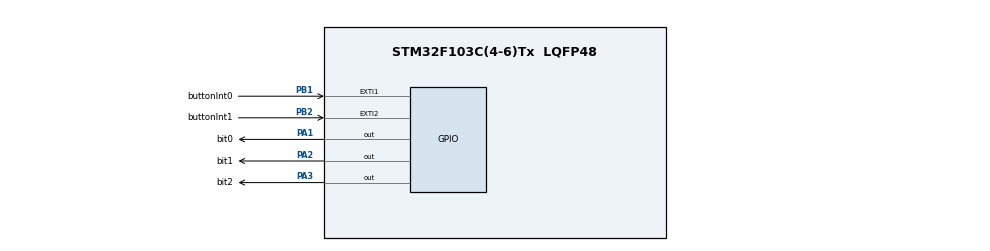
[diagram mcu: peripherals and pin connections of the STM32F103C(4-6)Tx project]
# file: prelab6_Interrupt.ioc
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Mcu.Family=STM32F1
Mcu.Name=STM32F103C(4-6)Tx
Mcu.Package=LQFP48
NVIC.EXTI1_IRQn=true\:2\:0\:true\:false\:true\:true\:true\:true
NVIC.EXTI2_IRQn=true\:3\:0\:true\:false\:true\:true\:true\:true
NVIC.PriorityGroup=NVIC_PRIORITYGROUP_4
PA1.GPIO_Label=bit0
PA1.Signal=GPIO_Output
PA2.GPIO_Label=bit1
PA2.Signal=GPIO_Output
PA3.GPIO_Label=bit2
PA3.Signal=GPIO_Output
PB1.GPIO_Label=buttonInt0
PB1.Signal=GPXTI1
PB2.GPIO_Label=buttonInt1
PB2.Signal=GPXTI2
ProjectManager.HeapSize=0x200
ProjectManager.StackSize=0x400
ProjectManager.TargetToolchain=MDK-ARM V5.32
RCC.APB1Freq_Value=8000000
RCC.APB2Freq_Value=8000000
VP_SYS_VS_ND.Mode=No_Debug
board=custom

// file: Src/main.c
/* USER CODE BEGIN Header */
/**
  ******************************************************************************
  * @file           : main.c
  * @brief          : Main program body
  ******************************************************************************
  * @attention
  *
  * Copyright (c) 2023 STMicroelectronics.
  * All rights reserved.
  *
  * This software is licensed under terms that can be found in the LICENSE file
  * in the root directory of this software component.
  * If no LICENSE file comes with this software, it is provided AS-IS.
  *
  ******************************************************************************
  */
/* USER CODE END Header */
#include "main.h"

/* USER CODE BEGIN PV */
	 uint16_t num_press = 0;
	 uint16_t timeSpend = 200;
/* USER CODE END PV */

void SystemClock_Config(void);
static void MX_GPIO_Init(void);

int main(void)
{

  /* MCU Configuration--------------------------------------------------------*/

  /* Reset of all peripherals, Initializes the Flash interface and the Systick. */
  HAL_Init();

  /* Configure the system clock */
  SystemClock_Config();

  /* Initialize all configured peripherals */
  MX_GPIO_Init();

  /* Infinite loop */
  /* USER CODE BEGIN WHILE */

  while (1)
  {
			HAL_Delay(timeSpend);
			update_leds(timeSpend);

    /* USER CODE END WHILE */

  }
}

void SystemClock_Config(void)
{
  RCC_OscInitTypeDef RCC_OscInitStruct = {0};
  RCC_ClkInitTypeDef RCC_ClkInitStruct = {0};

  /** Initializes the RCC Oscillators according to the specified parameters
  * in the RCC_OscInitTypeDef structure.
  */
  RCC_OscInitStruct.OscillatorType = RCC_OSCILLATORTYPE_HSI;
  RCC_OscInitStruct.HSIState = RCC_HSI_ON;
  RCC_OscInitStruct.HSICalibrationValue = RCC_HSICALIBRATION_DEFAULT;
  RCC_OscInitStruct.PLL.PLLState = RCC_PLL_NONE;
  if (HAL_RCC_OscConfig(&RCC_OscInitStruct) != HAL_OK)
  {
    Error_Handler();
  }

  /** Initializes the CPU, AHB and APB buses clocks
  */
  RCC_ClkInitStruct.ClockType = RCC_CLOCKTYPE_HCLK|RCC_CLOCKTYPE_SYSCLK
                              |RCC_CLOCKTYPE_PCLK1|RCC_CLOCKTYPE_PCLK2;
  RCC_ClkInitStruct.SYSCLKSource = RCC_SYSCLKSOURCE_HSI;
  RCC_ClkInitStruct.AHBCLKDivider = RCC_SYSCLK_DIV1;
  RCC_ClkInitStruct.APB1CLKDivider = RCC_HCLK_DIV1;
  RCC_ClkInitStruct.APB2CLKDivider = RCC_HCLK_DIV1;

  if (HAL_RCC_ClockConfig(&RCC_ClkInitStruct, FLASH_LATENCY_0) != HAL_OK)
  {
    Error_Handler();
  }
}

static void MX_GPIO_Init(void)
{
  GPIO_InitTypeDef GPIO_InitStruct = {0};

  /* GPIO Ports Clock Enable */
  __HAL_RCC_GPIOA_CLK_ENABLE();
  __HAL_RCC_GPIOB_CLK_ENABLE();

  /*Configure GPIO pin Output Level */
  HAL_GPIO_WritePin(GPIOA, bit0_Pin|bit1_Pin|bit2_Pin, GPIO_PIN_RESET);

  /*Configure GPIO pins : bit0_Pin bit1_Pin bit2_Pin */
  GPIO_InitStruct.Pin = bit0_Pin|bit1_Pin|bit2_Pin;
  GPIO_InitStruct.Mode = GPIO_MODE_OUTPUT_PP;
  GPIO_InitStruct.Pull = GPIO_NOPULL;
  GPIO_InitStruct.Speed = GPIO_SPEED_FREQ_LOW;
  HAL_GPIO_Init(GPIOA, &GPIO_InitStruct);

  /*Configure GPIO pins : buttonInt0_Pin buttonInt1_Pin */
  GPIO_InitStruct.Pin = buttonInt0_Pin|buttonInt1_Pin;
  GPIO_InitStruct.Mode = GPIO_MODE_IT_RISING;
  GPIO_InitStruct.Pull = GPIO_NOPULL;
  HAL_GPIO_Init(GPIOB, &GPIO_InitStruct);

  /* EXTI interrupt init*/
  HAL_NVIC_SetPriority(EXTI1_IRQn, 2, 0);
  HAL_NVIC_EnableIRQ(EXTI1_IRQn);

  HAL_NVIC_SetPriority(EXTI2_IRQn, 3, 0);
  HAL_NVIC_EnableIRQ(EXTI2_IRQn);

}

/* USER CODE BEGIN 4 */
void update_leds(uint16_t timeSpend){

			uint16_t myArray[7] ={0, 1, 2, 4, 2, 1, 0};
			num_press++;
			GPIO_PinState bit0_value, bit1_value, bit2_value;

			bit0_value = ( myArray[num_press % 7] & (uint16_t)1) ? GPIO_PIN_SET : GPIO_PIN_RESET;
			bit1_value = ( myArray[num_press % 7] & (uint16_t)2) ? GPIO_PIN_SET : GPIO_PIN_RESET;
			bit2_value = ( myArray[num_press % 7] & (uint16_t)4) ? GPIO_PIN_SET : GPIO_PIN_RESET;

		bit0_GPIO_Port->BSRR = (bit0_value ? bit0_Pin : (bit0_Pin << 16u)) | (bit1_value ? bit1_Pin : (bit1_Pin << 16u)) | (bit2_value ? bit2_Pin : (bit2_Pin << 16u));;

}
/* USER CODE END 4 */

void Error_Handler(void)
{
  __disable_irq();
  while (1)
  {
  }
}
